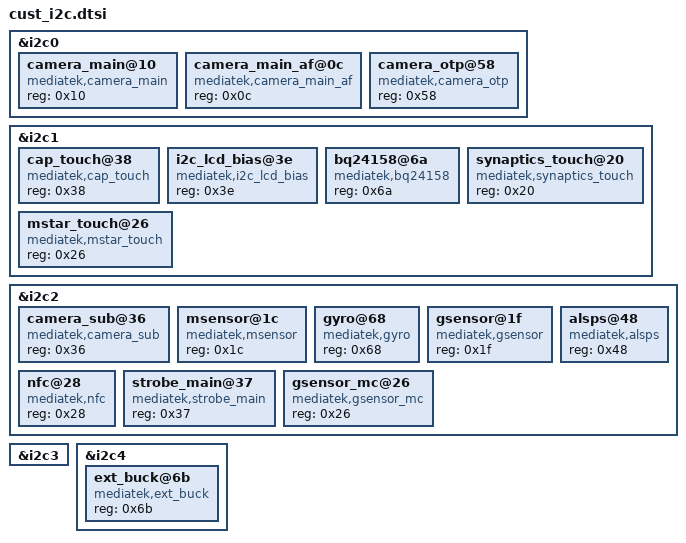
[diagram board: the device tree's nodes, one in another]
/*
 * Generated by MTK SP Drv_CodeGen Version 03.13.6	for MT6753. Copyright MediaTek Inc. (C) 2013.
 * Wed Jan 11 12:19:51 2017
 * Do Not Modify the File.
 */

/*************************
 * I2C DTSI File
*************************/

&i2c0 {
	#address-cells = <1>;
	#size-cells = <0>;
	camera_main@10 {
		compatible = "mediatek,camera_main";
		reg = <0x10>;
		status = "okay";
	};
	camera_main_af@0c {
		compatible = "mediatek,camera_main_af";
		reg = <0x0c>;
		status = "okay";
	};
	camera_otp@58 {
		compatible = "mediatek,camera_otp";
		reg = <0x58>;
		status = "okay";
	};
};

&i2c1 {
	#address-cells = <1>;
	#size-cells = <0>;
	cap_touch@38 {
		compatible = "mediatek,cap_touch";
		reg = <0x38>;
		status = "okay";
	};
	i2c_lcd_bias@3e {
		compatible = "mediatek,i2c_lcd_bias";
		reg = <0x3e>;
		status = "okay";
	};
	bq24158@6a {
		compatible = "mediatek,bq24158";
		reg = <0x6a>;
		status = "okay";
	};
	synaptics_touch@20 {
		compatible = "mediatek,synaptics_touch";
		reg = <0x20>;
		status = "okay";
	};
	mstar_touch@26 {
		compatible = "mediatek,mstar_touch";
		reg = <0x26>;
		status = "okay";
	};
};

&i2c2 {
	#address-cells = <1>;
	#size-cells = <0>;
	camera_sub@36 {
		compatible = "mediatek,camera_sub";
		reg = <0x36>;
		status = "okay";
	};
	msensor@1c {
		compatible = "mediatek,msensor";
		reg = <0x1c>;
		status = "okay";
	};
	gyro@68 {
		compatible = "mediatek,gyro";
		reg = <0x68>;
		status = "okay";
	};
	gsensor@1f {
		compatible = "mediatek,gsensor";
		reg = <0x1f>;
		status = "okay";
	};
	alsps@48 {
		compatible = "mediatek,alsps";
		reg = <0x48>;
		status = "okay";
	};
	nfc@28 {
		compatible = "mediatek,nfc";
		reg = <0x28>;
		status = "okay";
	};
	strobe_main@37 {
		compatible = "mediatek,strobe_main";
		reg = <0x37>;
		status = "okay";
	};
	gsensor_mc@26 {
		compatible = "mediatek,gsensor_mc";
		reg = <0x26>;
		status = "okay";
	};
};

&i2c3 {
	#address-cells = <1>;
	#size-cells = <0>;
};

&i2c4 {
	#address-cells = <1>;
	#size-cells = <0>;
	ext_buck@6b {
		compatible = "mediatek,ext_buck";
		reg = <0x6b>;
		status = "okay";
	};
};

